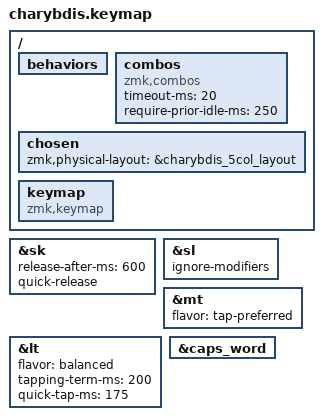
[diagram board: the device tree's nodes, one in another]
#include <behaviors.dtsi>
#include <dt-bindings/zmk/keys.h>
#include <dt-bindings/zmk/pointing.h>

// Layer definitions
#define BASE 0
#define MOUSE 1
#define SYMBOL 2
#define NUMBER 3
#define FUNCTION 4
#define GAME 5
#define RESET 6

// Key position groups for home row mods
#define KEYS_L 0 1 2 3 4 10 11 12 13 14 20 21 22 23 24  
#define KEYS_R 5 6 7 8 9 15 16 17 18 19 25 26 27 28 29
#define THUMBS 30 31 32 33 34 35  

&sk {
  release-after-ms = <600>;
  quick-release;
};

&sl {
  ignore-modifiers;
};

&mt {
  flavor = "tap-preferred";
};

&lt {
  flavor = "balanced";
  tapping-term-ms = <200>;
  quick-tap-ms = <175>;
};

&caps_word {
  /delete-property/ ignore-modifiers;
};

/ {
  behaviors {
    #include "behaviors/HT:home-row-mod:left.dtsi"
    #include "behaviors/HT:home-row-mod:right.dtsi"
    #include "behaviors/HT:home-row-mod-short:left.dtsi"
    #include "behaviors/HT:home-row-mod-short:right.dtsi"
    #include "behaviors/MM:smart-shift.dtsi"
  };

  combos {
    compatible = "zmk,combos";
    timeout-ms = <20>;
    require-prior-idle-ms = <250>;

    #include "combos/reset:left.dtsi"
    #include "combos/reset:right.dtsi"
    #include "combos/reset:central.dtsi"
    #include "combos/layer:normal.dtsi"
    #include "combos/layer:functions.dtsi"
    #include "combos/layer:game.dtsi"
    #include "combos/modded-key:ctrl-delete.dtsi"
    #include "combos/key:escape.dtsi"
    #include "combos/key:tab.dtsi"
    #include "combos/unlock.dtsi"
  };
  chosen {
    zmk,physical-layout = &charybdis_5col_layout;
  };

  keymap {
    compatible = "zmk,keymap";

    #include "layers/base:charybdis.dtsi"
    #include "layers/mouse.dtsi"
    #include "layers/symbols.dtsi"
    #include "layers/numbers.dtsi"
    #include "layers/functions.dtsi"
    #include "layers/game.dtsi"
    #include "layers/reset.dtsi"
  };
};
